# MCXN947_cm33_core0 register map
Vendor: nxp.com; File version: 1.0
CPU: CM33 r2p0, little endian, MPU, FPU, VTOR, 3 interrupt priority bits
Registers are 32-bit, read-write, reset 0x0 unless marked. A register's access mark holds for its fields unless they carry their own. Offsets are from the block's base; [hi:lo] are bit positions; {n}, {i} and the like mark numbered series; 'fields as' and 'values as' point back to an identical list.

## EMVSIM0 — EMVSIM
Base 0x40103000
Same registers: EMVSIM1 0x40104000
0x00 VER_ID ro — Version ID
  [31:0] VER
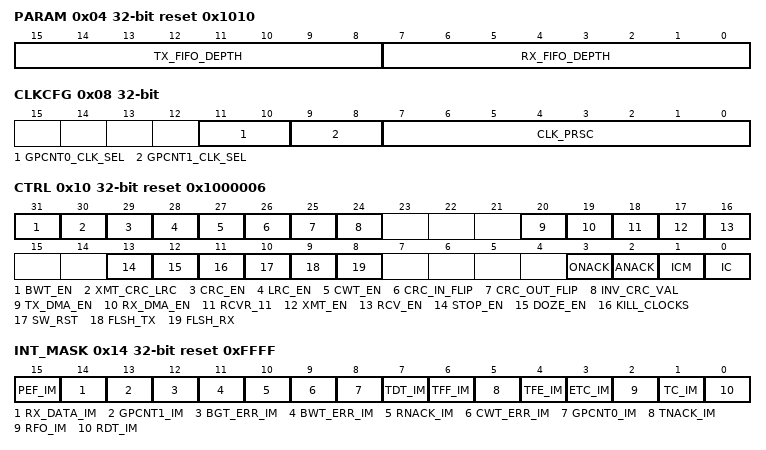
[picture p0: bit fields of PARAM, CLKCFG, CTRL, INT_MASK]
0x04 PARAM ro reset 0x1010 — Parameters
  [15:8] TX_FIFO_DEPTH — Transmit FIFO Depth
  [7:0] RX_FIFO_DEPTH — Receive FIFO Depth
0x08 CLKCFG — Clock Configuration
  [11:10] GPCNT0_CLK_SEL — General Purpose Counter 0 Clock Select
    0=disabled (Disable/reset); 1=cardclk (Card clock); 2=rxclk (Receive clock); 3=txclk (ETU clock (transmit clock))
  [9:8] GPCNT1_CLK_SEL — General Purpose Counter 1 Clock Select
    values as GPCNT0_CLK_SEL
  [7:0] CLK_PRSC — Clock Prescaler Value
0x0C DIVISOR reset 0x174 — Baud Rate Divisor
  [8:0] DIVISOR_VALUE — Divisor (F/D) Value
    {v}=invalid_{v} (Invalid. As per ISO 7816 specification, the minimum value of F/D is 5.) (v=0..4); {v}=valid_{v} (Divisor value F/D) (v=5..9)
0x10 CTRL reset 0x1000006 — Control
  [31] BWT_EN — Block Wait Time Counter Enable
    0=disabled; 1=enabled
  [30] XMT_CRC_LRC — Transmit CRC or LRC Enable
    0=no_crc_lrc_tx (Do not transmit); 1=crc_lrc_tx (Transmit)
  [29] CRC_EN — CRC Enable
    0=disabled; 1=enabled
  [28] LRC_EN — LRC Enable
    0=disabled; 1=enabled
  [27] CWT_EN — CWT Counter Enable
    0=disabled; 1=enabled
  [26] CRC_IN_FLIP — CRC Input Byte's Bit Reversal Or Flip Control
    0=not_reversed; 1=reversed
  [25] CRC_OUT_FLIP — CRC Output Value Bit Reversal Or Flip Control
    0=not_reversed; 1=reversed
  [24] INV_CRC_VAL — Invert CRC Output Value Bits
    0=no_invert (Not inverted); 1=Inverted
  [20] TX_DMA_EN — Transmit DMA Enable
    0=no_dmawrite_req (Not asserted); 1=dmawrite_req (Asserted)
  [19] RX_DMA_EN — Receive DMA Enable
    0=no_dmaread_req (Not asserted); 1=dmaread_req (Asserted)
  [18] RCVR_11 — Receiver 11 ETU Mode Enable
    0=rcvr_12 (12 ETU operation); 1=rcvr_11 (11 ETU operation)
  [17] XMT_EN — Transmitter Enable
    0=disabled; 1=enabled
  [16] RCV_EN — Receiver Enable
    0=disabled; 1=enabled
  [13] STOP_EN — STOP Enable
    0=stop_all_clks (Disable); 1=only_sck_on (Enable)
  [12] DOZE_EN — Doze Enable
    0=doze_gate (Disable); 1=doze_nogate (Enable)
  [11] KILL_CLOCKS — Kill Internal Clocks
    0=inclk_enabled (Enable); 1=inclk_disabled (Disable)
  [10] SW_RST — Software Reset
    0=normalop; 1=resethold
  [9] FLSH_TX — Flush Transmitter
    0=normalop; 1=resethold
  [8] FLSH_RX — Flush Receiver
    0=normalop; 1=resethold
  [3] ONACK — Overrun NACK Enable
    0=disabled; 1=enabled
  [2] ANACK — Auto NACK Enable
    0=disabled; 1=enabled
  [1] ICM — Initial Character Mode
    0=disabled; 1=enabled
  [0] IC — Inverse Convention
    0=dir_convention (Direct); 1=inv_convention (Inverse)
0x14 INT_MASK reset 0xFFFF — Interrupt Mask
  [15] PEF_IM — Parity Error Interrupt Mask
    0=int_enabled (Enable); 1=int_masked (Masked)
  [14] RX_DATA_IM — Receive Data Interrupt Mask
    0=int_enabled (Enable); 1=int_masked (Masked)
  [13] GPCNT1_IM — General Purpose Counter 1 Timeout Interrupt Mask
    0=int_enabled (Enable); 1=int_masked (Masked)
  [12] BGT_ERR_IM — Block Guard Time Error Interrupt
    0=int_enabled (Enable); 1=int_masked (Masked)
  [11] BWT_ERR_IM — Block Wait Time Error Interrupt Mask
    0=int_enabled (Enable); 1=int_masked (Masked)
  [10] RNACK_IM — Receiver NACK Threshold Interrupt Mask
    0=int_enabled (Enable); 1=int_masked (Masked)
  [9] CWT_ERR_IM — Character Wait Time Error Interrupt Mask
    0=int_enabled (Enable); 1=int_disabled (Masked)
  [8] GPCNT0_IM — General Purpose Timer 0 Timeout Interrupt Mask
    0=int_enabled (Enable); 1=int_masked (Masked)
  [7] TDT_IM — Transmit Data Threshold Interrupt Mask
    0=int_enabled (Enable); 1=int_masked (Masked)
  [6] TFF_IM — Transmit FIFO Full Interrupt Mask
    0=int_enabled (Enable); 1=int_masked (Masked)
  [5] TNACK_IM — Transmit NACK Threshold Interrupt Mask
    0=int_enabled (Enable); 1=int_masked (Masked)
  [4] TFE_IM — Transmit FIFO Empty Interrupt Mask
    0=int_enabled (Enable); 1=int_masked (Masked)
  [3] ETC_IM — Early Transmit Complete Interrupt Mask
    0=int_enabled (Enable); 1=int_masked (Masked)
  [2] RFO_IM — Receive FIFO Overflow Interrupt Mask
    0=int_enabled (Enable); 1=int_masked (Masked)
  [1] TC_IM — Transmit Complete Interrupt Mask
    0=int_enabled (Enable); 1=int_masked (Masked)
  [0] RDT_IM — Receive Data Threshold Interrupt Mask
    0=int_enabled (Enable); 1=int_masked (Masked)
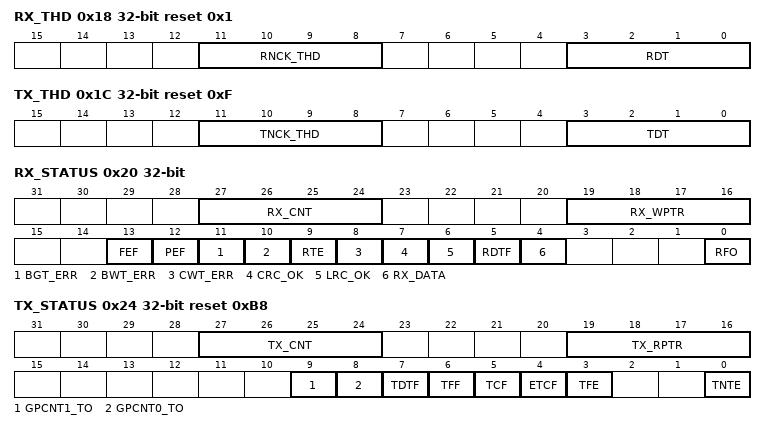
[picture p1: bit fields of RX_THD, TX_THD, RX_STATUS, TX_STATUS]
0x18 RX_THD reset 0x1 — Receiver Threshold
  [11:8] RNCK_THD — Receiver NACK Threshold Value
  [3:0] RDT — Receiver Data Threshold Value
0x1C TX_THD reset 0xF — Transmitter Threshold
  [11:8] TNCK_THD — Transmitter NACK Threshold Value
  [3:0] TDT — Transmitter Data Threshold Value
0x20 RX_STATUS — Receive Status
  [27:24] RX_CNT ro — Receive FIFO Byte Count
    0=fifo_empty
  [19:16] RX_WPTR ro — Receive FIFO Write Pointer Value
  [13] FEF write-1-clears — Frame Error Flag
    0=no_fef_detect (No error); 1=fef_detect (Error)
  [12] PEF write-1-clears — Parity Error Flag
    0=no_parity_detect (No error); 1=parity_detect (Error)
  [11] BGT_ERR write-1-clears — Block Guard Time Error Flag
    0=bgt_err_sufficient (Sufficient); 1=bgt_err_toosmall (Too small)
  [10] BWT_ERR write-1-clears — Block Wait Time Error Flag
    0=bwt_err_no (Not exceeded); 1=bwt_err_yes (Exceeded)
  [9] RTE write-1-clears — Received NACK Threshold Error Flag
    0=lessthan_nackthresh; 1=greater_eq_nackthresh (Equal to)
  [8] CWT_ERR write-1-clears — Character Wait Time Error Flag
    0=no_cwt_err (No CWT violation); 1=cwt_err (CWT violation)
  [7] CRC_OK ro — CRC Check OK Flag
    0=crc_notok (Current CRC value does not match remainder.); 1=crc_ok (Current calculated CRC value matches the expected result.)
  [6] LRC_OK ro — LRC Check OK Flag
    0=lrc_notok (No match); 1=lrc_ok (Match)
  [5] RDTF ro — Receive Data Threshold Interrupt Flag
    0=lessthan_rxthresh (Less than threshold); 1=greater_eq_rxthresh (Greater than or equal to threshold)
  [4] RX_DATA write-1-clears — Receive Data Interrupt Flag
    0=no_byte_rx (No new byte); 1=byte_rx (New byte)
  [0] RFO write-1-clears — Receive FIFO Overflow Flag
    0=No overrun error; 1=overflow (Overrun error)
0x24 TX_STATUS reset 0xB8 — Transmitter Status
  [27:24] TX_CNT ro — Transmit FIFO Byte Count
    0=fifo_empty
  [19:16] TX_RPTR ro — Transmit FIFO Read Pointer
  [9] GPCNT1_TO write-1-clears — General Purpose Counter 1 Timeout Flag
    0=gpcnt1_to_notreached (GPCNT1 not reached, or flag cleared); 1=gpcnt1_to_reached (GPCNT1 reached)
  [8] GPCNT0_TO write-1-clears — General Purpose Counter 0 Timeout Flag
    0=gpcnt0_to_notreached (GPCNT0 not reached, or flag cleared); 1=gpcnt0_to_reached (GPCNT0 reached)
  [7] TDTF ro — Transmit Data Threshold Flag
    0=lessthan_txthresh (Threshold exceeded or this field written to 0); 1=greater_eq_txthresh (Threshold not exceeded)
  [6] TFF write-1-clears — Transmit FIFO Full Flag
    0=tx_fifo_notfull (Not full); 1=tx_fifo_full (Full)
  [5] TCF write-1-clears — Transmit Complete Flag
    0=tx_pending (Pending or incomplete); 1=tx_complete (Complete)
  [4] ETCF write-1-clears — Early Transmit Complete Flag
    0=etx_pending (Pending or incomplete); 1=etx_complete (Complete)
  [3] TFE write-1-clears — Transmit FIFO Empty Flag
    0=fifo_empty (Not empty); 1=fifo_notempty (Empty)
  [0] TNTE write-1-clears — Transmit NACK Threshold Error Flag
    0=lessthan_nackthresh (Threshold not reached); 1=greater_eq_nackthresh (Threshold reached)
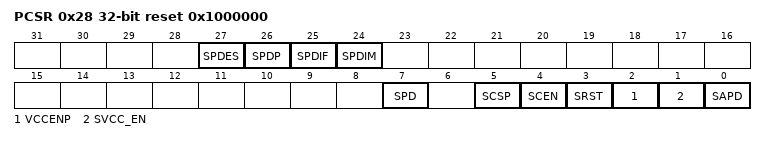
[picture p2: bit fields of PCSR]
0x28 PCSR reset 0x1000000 — Port Control and Status
  [27] SPDES — SIM Presence Detect Edge Select
    0=falling_edge; 1=rising_edge
  [26] SPDP ro — Smart Card Presence Detect Pin Status
    0=logic_low; 1=logic_high
  [25] SPDIF write-1-clears — Smart Card Presence Detect Interrupt Flag
    0=no_insert_remove_detect (No insertion or removal); 1=insert_remove_detect (Insertion or removal)
  [24] SPDIM — Smart Card Presence Detect Interrupt Mask
    0=int_enabled (Enable); 1=int_masked (Mask)
  [7] SPD — Auto Power-Down Control
    0=no_effect; 1=powerdown (Yes)
  [5] SCSP — Smart Card Clock Stop Polarity
    0=scsp_logic0 (Logic 0); 1=scsp_logic1 (Logic 1)
  [4] SCEN — Clock Enable for Smart Card
    0=disabled; 1=enabled
  [3] SRST — Reset Smart Card
    0=asserted; 1=de_asserted
  [2] VCCENP — VCC Enable Polarity Control
    0=active_high; 1=active_low
  [1] SVCC_EN — Vcc Enable for Smart Card
    0=disabled; 1=enabled
  [0] SAPD — Auto Power Down Enable
    0=disabled; 1=enabled
0x2C RX_BUF ro — Receive Data Read Buffer
  [7:0] RX_BYTE — Receive Data Byte Read
0x30 TX_BUF — Transmit Data Buffer
  [7:0] TX_BYTE — Transmit Data Byte
0x34 TX_GETU — Transmitter Guard ETU Value
  [7:0] GETU — Transmitter Guard Time Value in ETU
0x38 CWT_VAL reset 0xFFFF — Character Wait Time Value
  [15:0] CWT
0x3C BWT_VAL reset 0xFFFFFFFF — Block Wait Time Value
  [31:0] BWT
0x40 BGT_VAL — Block Guard Time Value
  [15:0] BGT
0x44 GPCNT0_VAL reset 0xFFFF — General Purpose Counter 0 Timeout Value
  [15:0] GPCNT0
0x48 GPCNT1_VAL reset 0xFFFF — General Purpose Counter 1 Timeout Value
  [15:0] GPCNT1
